# nrf9230_engb_cellrf register map
Vendor: Nordic Semiconductor; Series: nRF92; File version: 1
CPU: CM0 r0p0, little endian, no MPU, no FPU, 2 interrupt priority bits, 33 interrupts
Registers are 32-bit, read-write, reset 0x0 unless marked. A register's access mark holds for its fields unless they carry their own. Offsets are from the block's base; [hi:lo] are bit positions; {n}, {i} and the like mark numbered series; 'fields as' and 'values as' point back to an identical list.

## EGUTX — Event generator unit 0
Base 0x46022000
Same registers: EGURX 0x46033000, GLOBAL_EGU130 0x5F92D000
{0x0+4i} TASKS_TRIGGER[{i}] (i=0..15) wo — Description collection: Trigger n for triggering the corresponding TRIGGERED[n] event
  [0] TASKS_TRIGGER — Trigger n for triggering the corresponding TRIGGERED[n] event
    1=Trigger task
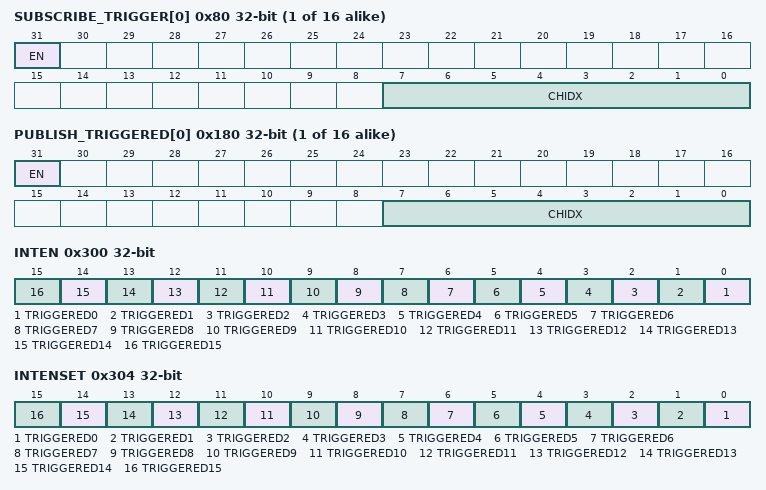
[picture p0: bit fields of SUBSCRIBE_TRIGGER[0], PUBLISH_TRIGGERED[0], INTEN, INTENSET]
{0x80+4i} SUBSCRIBE_TRIGGER[{i}] (i=0..15) — Description collection: Subscribe configuration for task TRIGGER[n]
  [31] EN
    0=Disabled (Disable subscription); 1=Enabled (Enable subscription)
  [7:0] CHIDX — DPPI channel that task TRIGGER[n] will subscribe to
{0x100+4i} EVENTS_TRIGGERED[{i}] (i=0..15) — Description collection: Event number n generated by triggering the corresponding TRIGGER[n] task
  [0] EVENTS_TRIGGERED — Event number n generated by triggering the corresponding TRIGGER[n] task
    0=NotGenerated (Event not generated); 1=Generated (Event generated)
{0x180+4i} PUBLISH_TRIGGERED[{i}] (i=0..15) — Description collection: Publish configuration for event TRIGGERED[n]
  [31] EN
    0=Disabled (Disable publishing); 1=Enabled (Enable publishing)
  [7:0] CHIDX — DPPI channel that event TRIGGERED[n] will publish to
0x300 INTEN — Enable or disable interrupt
  [all] fields
    0=Disabled; 1=Enabled
  [n] TRIGGERED{n} (n=0..15) — Enable or disable interrupt for event TRIGGERED[{n}]
0x304 INTENSET — Enable interrupt
  [all] fields
    on read: 0=Disabled (Read: Disabled); 1=Enabled (Read: Enabled) | on write: 1=Set (Enable)
  [n] TRIGGERED{n} (n=0..15) — Write '1' to enable interrupt for event TRIGGERED[{n}]
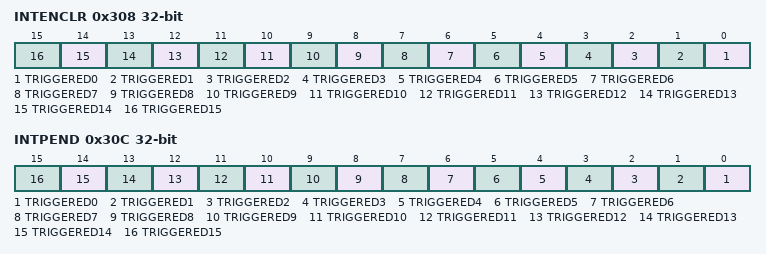
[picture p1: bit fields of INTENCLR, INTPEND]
0x308 INTENCLR — Disable interrupt
  [all] fields
    on read: 0=Disabled (Read: Disabled); 1=Enabled (Read: Enabled) | on write: 1=Clear (Disable)
  [n] TRIGGERED{n} (n=0..15) — Write '1' to disable interrupt for event TRIGGERED[{n}]
0x30C INTPEND ro — Pending interrupts
  [all] fields
    on read: 0=NotPending (Read: Not pending); 1=Pending (Read: Pending)
  [n] TRIGGERED{n} (n=0..15) — Read pending status of interrupt for event TRIGGERED[{n}]

## BELLBOARD — BELLBOARD APB registers
Base 0x4F09E000
{0x0+4i} TASKS_TRIGGER[{i}] (i=0..31) wo — Description collection: Task TRIGGER[n]
  [0] TASKS_TRIGGER — Task TRIGGER[n]
    1=Trigger task
{0x100+4i} EVENTS_TRIGGERED[{i}] (i=0..31) — Description collection: Event TRIGGERED[n]
  [0] EVENTS_TRIGGERED — Event TRIGGERED[n]
    0=NotGenerated (Event not generated); 1=Generated (Event generated)
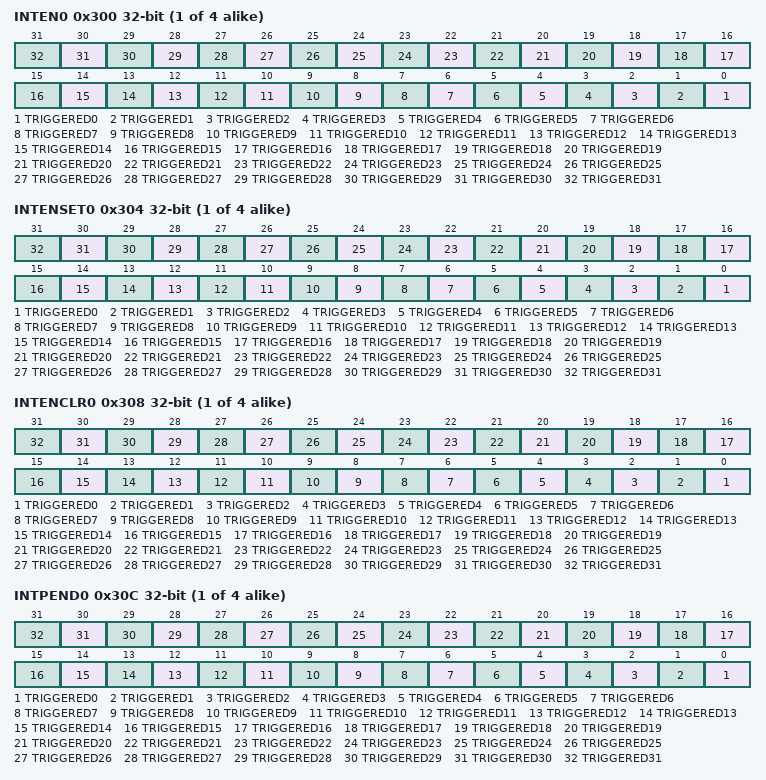
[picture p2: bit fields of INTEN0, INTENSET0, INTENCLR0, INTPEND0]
{0x300+0x10*i} INTEN{i} (i=0..3) — Enable or disable interrupt
  [all] fields
    0=Disabled; 1=Enabled
  [n] TRIGGERED{n} (n=0..31) — Enable or disable interrupt for event TRIGGERED[{n}]
{0x304+0x10*i} INTENSET{i} (i=0..3) — Enable interrupt
  [all] fields
    on read: 0=Disabled (Read: Disabled); 1=Enabled (Read: Enabled) | on write: 1=Set (Enable)
  [n] TRIGGERED{n} (n=0..31) — Write '1' to enable interrupt for event TRIGGERED[{n}]
{0x308+0x10*i} INTENCLR{i} (i=0..3) — Disable interrupt
  [all] fields
    on read: 0=Disabled (Read: Disabled); 1=Enabled (Read: Enabled) | on write: 1=Clear (Disable)
  [n] TRIGGERED{n} (n=0..31) — Write '1' to disable interrupt for event TRIGGERED[{n}]
{0x30C+0x10*i} INTPEND{i} ro (i=0..3) — Pending interrupts
  [all] fields
    on read: 0=NotPending (Read: Not pending); 1=Pending (Read: Pending)
  [n] TRIGGERED{n} (n=0..31) — Read pending status of interrupt for event TRIGGERED[{n}]

## GLOBAL_TBM — Trace buffer monitor
Base 0xBF003000
0x00 TASKS_START wo — Start counter
  [0] TASKS_START
    1=Trigger task
0x04 TASKS_STOP wo — Stop counter, clear counter value
  [0] TASKS_STOP
    1=Trigger task
0x08 TASKS_FLUSH wo — Save current counter value to COUNTSNAPSHOT
  [0] TASKS_FLUSH
    1=Trigger task
0x100 EVENTS_HALFFULL — Counter value equals half-full
  [0] EVENTS_HALFFULL
    0=NotGenerated (Event not generated); 1=Generated (Event generated)
0x104 EVENTS_FULL — Counter value equals full
  [0] EVENTS_FULL
    values as EVENTS_HALFFULL.EVENTS_HALFFULL
0x108 EVENTS_FLUSH — Counter value saved to COUNTSNAPSHOT due to flush
  [0] EVENTS_FLUSH
    values as EVENTS_HALFFULL.EVENTS_HALFFULL
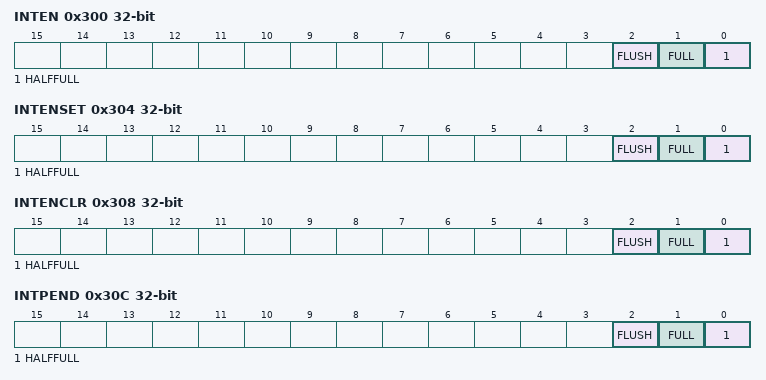
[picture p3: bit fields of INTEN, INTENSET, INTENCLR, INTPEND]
0x300 INTEN — Enable or disable interrupt
  [all] fields
    0=Disabled; 1=Enabled
  [2] FLUSH — Enable or disable interrupt for event FLUSH
  [1] FULL — Enable or disable interrupt for event FULL
  [0] HALFFULL — Enable or disable interrupt for event HALFFULL
0x304 INTENSET — Enable interrupt
  [all] fields
    on read: 0=Disabled (Read: Disabled); 1=Enabled (Read: Enabled) | on write: 1=Set (Enable)
  [2] FLUSH — Write '1' to enable interrupt for event FLUSH
  [1] FULL — Write '1' to enable interrupt for event FULL
  [0] HALFFULL — Write '1' to enable interrupt for event HALFFULL
0x308 INTENCLR — Disable interrupt
  [all] fields
    on read: 0=Disabled (Read: Disabled); 1=Enabled (Read: Enabled) | on write: 1=Clear (Disable)
  [2] FLUSH — Write '1' to disable interrupt for event FLUSH
  [1] FULL — Write '1' to disable interrupt for event FULL
  [0] HALFFULL — Write '1' to disable interrupt for event HALFFULL
0x30C INTPEND ro — Pending interrupts
  [all] fields
    on read: 0=NotPending (Read: Not pending); 1=Pending (Read: Pending)
  [2] FLUSH — Read pending status of interrupt for event FLUSH
  [1] FULL — Read pending status of interrupt for event FULL
  [0] HALFFULL — Read pending status of interrupt for event HALFFULL
0x400 BUFFERSIZE reset 0x400 — System RAM trace buffer total size in bytes
  [12:0] BUFFERSIZE — Must only be configured in STOP mode. Must be programmed to multiple of 16 bytes to make half-buffer size always 64 bit word aligned. Typical minimum BUFFERSIZE value 0x010 i.e. 16 bytes, typical maximum value 0x1000 i.e. 4096 bytes.
    0=Zero (0 bytes); 16=Min (16 bytes); 0x1000=Max (4096 bytes)
0x404 COUNT — Counter current value
  [12:0] COUNT — Counter current value. Only writable when counter is in stopped state. Writing when not in stopped state will generate a bus fault.
0x408 COUNTSNAPSHOT ro — Copy of the current COUNT value
  [12:0] COUNTSNAPSHOT — TASKS_FLUSH will copy the current COUNT value to this register.
